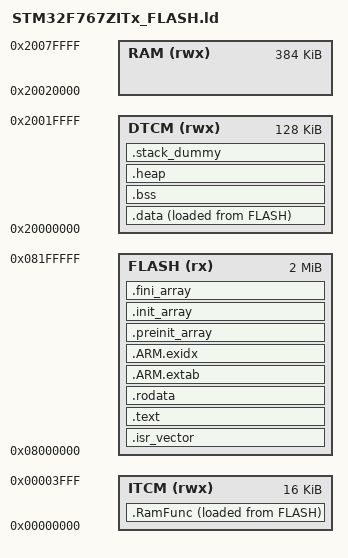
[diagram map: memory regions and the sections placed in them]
/*
******************************************************************************
**

**  File        : LinkerScript.ld
**
**  Author		: Auto-generated by System Workbench for STM32
**
**  Abstract    : Linker script for STM32F767ZITx series
**                2048Kbytes FLASH and 512Kbytes RAM
**
**                Set heap size, stack size and stack location according
**                to application requirements.
**
**                Set memory bank area and size if external memory is used.
**
**  Target      : STMicroelectronics STM32
**
**  Distribution: The file is distributed “as is,” without any warranty
**                of any kind.
**
*****************************************************************************
** @attention
**
** <h2><center>&copy; COPYRIGHT(c) 2019 STMicroelectronics</center></h2>
**
** Redistribution and use in source and binary forms, with or without modification,
** are permitted provided that the following conditions are met:
**   1. Redistributions of source code must retain the above copyright notice,
**      this list of conditions and the following disclaimer.
**   2. Redistributions in binary form must reproduce the above copyright notice,
**      this list of conditions and the following disclaimer in the documentation
**      and/or other materials provided with the distribution.
**   3. Neither the name of STMicroelectronics nor the names of its contributors
**      may be used to endorse or promote products derived from this software
**      without specific prior written permission.
**
** THIS SOFTWARE IS PROVIDED BY THE COPYRIGHT HOLDERS AND CONTRIBUTORS "AS IS"
** AND ANY EXPRESS OR IMPLIED WARRANTIES, INCLUDING, BUT NOT LIMITED TO, THE
** IMPLIED WARRANTIES OF MERCHANTABILITY AND FITNESS FOR A PARTICULAR PURPOSE ARE
** DISCLAIMED. IN NO EVENT SHALL THE COPYRIGHT HOLDER OR CONTRIBUTORS BE LIABLE
** FOR ANY DIRECT, INDIRECT, INCIDENTAL, SPECIAL, EXEMPLARY, OR CONSEQUENTIAL
** DAMAGES (INCLUDING, BUT NOT LIMITED TO, PROCUREMENT OF SUBSTITUTE GOODS OR
** SERVICES; LOSS OF USE, DATA, OR PROFITS; OR BUSINESS INTERRUPTION) HOWEVER
** CAUSED AND ON ANY THEORY OF LIABILITY, WHETHER IN CONTRACT, STRICT LIABILITY,
** OR TORT (INCLUDING NEGLIGENCE OR OTHERWISE) ARISING IN ANY WAY OUT OF THE USE
** OF THIS SOFTWARE, EVEN IF ADVISED OF THE POSSIBILITY OF SUCH DAMAGE.
**
*****************************************************************************
*/

/* Entry Point */
ENTRY(_start)

/* Specify the memory areas */
MEMORY
{
  ITCM (rwx)      : ORIGIN = 0x00000000, LENGTH = 16K
  DTCM (rwx)      : ORIGIN = 0x20000000, LENGTH = 128K
  RAM (rwx)       : ORIGIN = 0x20020000, LENGTH = 384K
  FLASH (rx)      : ORIGIN = 0x08000000, LENGTH = 2048K
}

/* Define output sections */
SECTIONS
{
  /* The startup code goes first into FLASH */
  .isr_vector : ALIGN(4)
  {
    KEEP(*(.isr_vector)) /* Startup code */
    . = 0x200; /* End of vector table */
  } > FLASH

  /* The program code and other data goes into FLASH */
  .text : ALIGN(4)
  {
    *(.text)           /* .text sections (code) */
    *(.text*)          /* .text* sections (code) */
    *(.glue_7)         /* glue arm to thumb code */
    *(.glue_7t)        /* glue thumb to arm code */
    KEEP(*(.eh_frame))

    KEEP(*(.init))
    KEEP(*(.fini))

    /* .ctors */
    *crtbegin.o(.ctors)
    *crtbegin?.o(.ctors)
    *(EXCLUDE_FILE(*crtend?.o *crtend.o) .ctors)
    *(SORT(.ctors.*))
    *(.ctors)

    /* .dtors */
    *crtbegin.o(.dtors)
    *crtbegin?.o(.dtors)
    *(EXCLUDE_FILE(*crtend?.o *crtend.o) .dtors)
    *(SORT(.dtors.*))
    *(.dtors)
  } > FLASH

  /* Constants, strings, etc. go into FLASH */
  .rodata : { *(.rodata .rodata* .gnu.linkonce.r.*) } > FLASH

  .ARM.extab : { *(.ARM.extab* .gnu.linkonce.armextab.*) } > FLASH
  __exidx_start = .;
  .ARM.exidx : { *(.ARM.exidx* .gnu.linkonce.armexidx.*) } > FLASH
  __exidx_end = .;

  __etext = ALIGN(4);
  PROVIDE(_etext = __etext);
  PROVIDE(etext = __etext);

  .preinit_array :
  {
    PROVIDE_HIDDEN (__preinit_array_start = .);
    KEEP (*(.preinit_array*))
    PROVIDE_HIDDEN (__preinit_array_end = .);
  } > FLASH
  .init_array :
  {
    PROVIDE_HIDDEN (__init_array_start = .);
    KEEP (*(SORT_BY_INIT_PRIORITY(.init_array.*) SORT_BY_INIT_PRIORITY(.ctors.*)))
    KEEP (*(.init_array EXCLUDE_FILE (*crtbegin.o *crtbegin?.o *crtend.o *crtend?.o ) .ctors))
    PROVIDE_HIDDEN (__init_array_end = .);
  } > FLASH
  .fini_array :
  {
    PROVIDE_HIDDEN (__fini_array_start = .);
    KEEP (*(SORT_BY_INIT_PRIORITY(.fini_array.*) SORT_BY_INIT_PRIORITY(.dtors.*)))
    KEEP (*(.fini_array EXCLUDE_FILE (*crtbegin.o *crtbegin?.o *crtend.o *crtend?.o ) .dtors))
    PROVIDE_HIDDEN (__fini_array_end = .);
  } > FLASH

  /* Initialized data sections goes into RAM, load LMA copy after code */
  .data : ALIGN(4)
  {
    __data_start = .;   /* create a global symbol at data start */
    __data_start__ = .;
    *(vtable)
    *(.data)            /* .data sections */
    *(.data*)           /* .data* sections */
    *(.gnu.linkonce.d.*)

    . = ALIGN(4);
    __data_end = .;     /* define a global symbol at data end */
    __data_end__ = .;
  } > DTCM AT> FLASH

  /* used by the startup to initialize data */
  __data_loadaddr = LOADADDR(.data);
  __data_size = SIZEOF(.data);

  /* Load RAM_FUNCs into ITCM RAM */
  .RamFunc : ALIGN(4)
  {
    __ramfunc_start = .;
    *(.RamFunc)

    . = ALIGN(4);
    __ramfunc_end = .;
  } > ITCM AT> FLASH

  /* used by the startup to initialize RAM_FUNCs */
  __ramfunc_loadaddr = LOADADDR(.RamFunc);
  __ramfunc_size = SIZEOF(.RamFunc);

  /* Uninitialized data section */
  .bss : ALIGN(4)
  {
    /* This is used by the startup in order to initialize the .bss secion */
    __bss_start = .;      /* define a global symbol at bss start */
    __bss_start__ = .;
    *(.bss)
    *(.bss*)
    *(COMMON)

    . = ALIGN(4);
    __bss_end = .;        /* define a global symbol at bss end */
    __bss_end__ = .;
  } > DTCM


  .heap (COPY) : ALIGN(8)
  {
    __end__ = .;
    PROVIDE(_end = .);
    PROVIDE(end = .);
    KEEP(*(.heap*));
    . = ALIGN(8);
    __HeapLimit = .;
  } > DTCM

  /* .stack_dummy section doesn't contains any symbols. It is only
   * used for linker to calculate size of stack sections, and assign
   * values to stack symbols later */
  .stack_dummy (COPY) : ALIGN(8)
  {
    KEEP(*(.stack*));
    . = ALIGN(8);
  } > DTCM

  /* Highest address of the user mode stack */
  __StackTop = ORIGIN(DTCM) + LENGTH(DTCM);   /* end of DTCM RAM */
  PROVIDE(__stack = __StackTop);

  __StackLimit = __StackTop - SIZEOF(.stack_dummy);

  /* Check if data + heap + stack exceeds RAM limit */
  ASSERT(__StackLimit >= __HeapLimit, "region RAM overflowed with stack")

  /* Remove information from the standard libraries */
  /DISCARD/ :
  {
    libc.a ( * )
    libm.a ( * )
    libgcc.a ( * )
    *(.gnu_debuglink)
    *(.gnu.lto_*)
  }

  .ARM.attributes 0 : { *(.ARM.attributes) }
}
